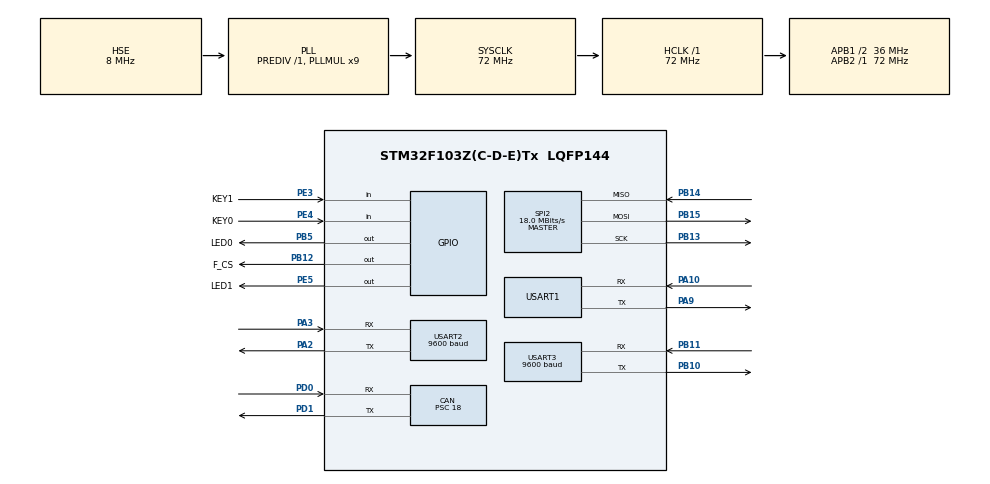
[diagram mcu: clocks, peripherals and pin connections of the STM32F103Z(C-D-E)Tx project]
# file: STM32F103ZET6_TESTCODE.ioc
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CAN.BS2=CAN_BS2_2TQ
CAN.CalculateBaudRate=500000
CAN.CalculateTimeBit=2000
CAN.CalculateTimeQuantum=500.0
CAN.Prescaler=18
FREERTOS.Queues01=ShortQueue,16,uint16_t,0,Dynamic,NULL,NULL;LongQueue,128,uint16_t,0,Dynamic,NULL,NULL
FREERTOS.Tasks01=Start_Task,24,128,Start_Thread,Default,NULL,Dynamic,NULL,NULL;Mb_Master,8,512,Mb_Master_Thread,Default,NULL,Dynamic,NULL,NULL;Mb_Slaver,8,512,Mb_Slaver_Thread,Default,NULL,Dynamic,NULL,NULL;PE_Comm,8,512,PE_Comm_Thread,Default,NULL,Dynamic,NULL,NULL;Ymbdem,8,2048,Ymbdem_Thread,Default,NULL,Dynamic,NULL,NULL;Task_Mem,8,1024,Task_Mem_Thread,Default,NULL,Dynamic,NULL,NULL
FREERTOS.configCHECK_FOR_STACK_OVERFLOW=2
FREERTOS.configTOTAL_HEAP_SIZE=0x8000
Mcu.Family=STM32F1
Mcu.Name=STM32F103Z(C-D-E)Tx
Mcu.Package=LQFP144
NVIC.PriorityGroup=NVIC_PRIORITYGROUP_4
NVIC.SPI2_IRQn=true\:6\:0\:true\:false\:true\:true\:true\:true\:true
NVIC.TIM6_IRQn=true\:7\:0\:true\:false\:true\:true\:true\:true\:true
NVIC.USART1_IRQn=true\:7\:0\:true\:false\:true\:true\:true\:true\:true
NVIC.USART2_IRQn=true\:7\:0\:true\:false\:true\:true\:true\:true\:true
NVIC.USART3_IRQn=true\:7\:0\:true\:false\:true\:true\:true\:true\:true
NVIC.USB_LP_CAN1_RX0_IRQn=true\:8\:0\:true\:false\:true\:true\:true\:true\:true
OSC_IN.Mode=HSE-External-Oscillator
OSC_IN.Signal=RCC_OSC_IN
OSC_OUT.Mode=HSE-External-Oscillator
OSC_OUT.Signal=RCC_OSC_OUT
PA10.Mode=Asynchronous
PA10.Signal=USART1_RX
PA13.Mode=JTAG_5_pins
PA13.Signal=SYS_JTMS-SWDIO
PA14.Mode=JTAG_5_pins
PA14.Signal=SYS_JTCK-SWCLK
PA15.Mode=JTAG_5_pins
PA15.Signal=SYS_JTDI
PA2.Mode=Asynchronous
PA2.Signal=USART2_TX
PA3.Mode=Asynchronous
PA3.Signal=USART2_RX
PA9.Mode=Asynchronous
PA9.Signal=USART1_TX
PB10.Mode=Asynchronous
PB10.Signal=USART3_TX
PB11.Mode=Asynchronous
PB11.Signal=USART3_RX
PB12.GPIO_Label=F_CS
PB12.GPIO_PuPd=GPIO_PULLUP
PB12.GPIO_Speed=GPIO_SPEED_FREQ_HIGH
PB12.Signal=GPIO_Output
PB13.Mode=Full_Duplex_Master
PB13.Signal=SPI2_SCK
PB14.Mode=Full_Duplex_Master
PB14.Signal=SPI2_MISO
PB15.Mode=Full_Duplex_Master
PB15.Signal=SPI2_MOSI
PB3.Mode=JTAG_5_pins
PB3.Signal=SYS_JTDO-TRACESWO
PB4.Mode=JTAG_5_pins
PB4.Signal=SYS_NJTRST
PB5.GPIO_Label=LED0
PB5.GPIO_PuPd=GPIO_PULLUP
PB5.GPIO_Speed=GPIO_SPEED_FREQ_HIGH
PB5.Signal=GPIO_Output
PC14-OSC32_IN.Mode=LSE-External-Oscillator
PC14-OSC32_IN.Signal=RCC_OSC32_IN
PC15-OSC32_OUT.Mode=LSE-External-Oscillator
PC15-OSC32_OUT.Signal=RCC_OSC32_OUT
PD0.Mode=CAN_Activate
PD0.Signal=CAN_RX
PD1.Mode=CAN_Activate
PD1.Signal=CAN_TX
PE3.GPIO_Label=KEY1
PE3.Signal=GPIO_Input
PE4.GPIO_Label=KEY0
PE4.Signal=GPIO_Input
PE5.GPIO_Label=LED1
PE5.GPIO_PuPd=GPIO_PULLUP
PE5.GPIO_Speed=GPIO_SPEED_FREQ_HIGH
PE5.Signal=GPIO_Output
ProjectManager.HeapSize=0x200
ProjectManager.StackSize=0x400
ProjectManager.TargetToolchain=MDK-ARM V5.32
RCC.AHBFreq_Value=72000000
RCC.APB1CLKDivider=RCC_HCLK_DIV2
RCC.APB1Freq_Value=36000000
RCC.APB1TimFreq_Value=72000000
RCC.APB2Freq_Value=72000000
RCC.APB2TimFreq_Value=72000000
RCC.HCLKFreq_Value=72000000
RCC.PLLMUL=RCC_PLL_MUL9
RCC.PLLSourceVirtual=RCC_PLLSOURCE_HSE
RCC.SYSCLKFreq_VALUE=72000000
RCC.SYSCLKSource=RCC_SYSCLKSOURCE_PLLCLK
RCC.USBFreq_Value=72000000
SPI2.BaudRatePrescaler=SPI_BAUDRATEPRESCALER_2
SPI2.CLKPhase=SPI_PHASE_1EDGE
SPI2.CLKPolarity=SPI_POLARITY_LOW
SPI2.CalculateBaudRate=18.0 MBits/s
SPI2.Direction=SPI_DIRECTION_2LINES
SPI2.Mode=SPI_MODE_MASTER
SPI2.VirtualType=VM_MASTER
TIM6.AutoReloadPreload=TIM_AUTORELOAD_PRELOAD_ENABLE
TIM6.Period=4999
TIM6.Prescaler=143
USART1.VirtualMode=VM_ASYNC
USART2.BaudRate=9600
USART2.VirtualMode=VM_ASYNC
USART3.BaudRate=9600
USART3.VirtualMode=VM_ASYNC
VP_FREERTOS_VS_CMSIS_V2.Mode=CMSIS_V2
VP_IWDG_VS_IWDG.Mode=IWDG_Activate
VP_RTC_VS_RTC_Activate.Mode=RTC_Enabled
VP_RTC_VS_RTC_Calendar.Mode=RTC_Calendar
VP_TIM6_VS_ClockSourceINT.Mode=Enable_Timer
board=custom

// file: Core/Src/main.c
/* USER CODE BEGIN Header */
/**
  ******************************************************************************
  * @file           : main.c
  * @brief          : Main program body
  ******************************************************************************
  * @attention
  *
  * Copyright (c) 2022 STMicroelectronics.
  * All rights reserved.
  *
  * This software is licensed under terms that can be found in the LICENSE file
  * in the root directory of this software component.
  * If no LICENSE file comes with this software, it is provided AS-IS.
  *
  ******************************************************************************
  */
/* USER CODE END Header */
#include "main.h"
#include "cmsis_os.h"
#include "can.h"
#include "iwdg.h"
#include "rtc.h"
#include "spi.h"
#include "tim.h"
#include "usart.h"
#include "gpio.h"

void SystemClock_Config(void);
void MX_FREERTOS_Init(void);

int main(void)
{

  /* MCU Configuration--------------------------------------------------------*/

  /* Reset of all peripherals, Initializes the Flash interface and the Systick. */
  HAL_Init();

  /* Configure the system clock */
  SystemClock_Config();

  /* Initialize all configured peripherals */
  MX_GPIO_Init();
  MX_CAN_Init();
//  MX_IWDG_Init();
  MX_RTC_Init();
  MX_SPI2_Init();
  MX_USART1_UART_Init();
  MX_USART2_UART_Init();
  MX_TIM6_Init();
  MX_USART3_UART_Init();

  /* Init scheduler */
  osKernelInitialize();  /* Call init function for freertos objects (in freertos.c) */
  MX_FREERTOS_Init();

  /* Start scheduler */
  osKernelStart();

  /* We should never get here as control is now taken by the scheduler */
  /* Infinite loop */
  while (1)
  {

  }
}

void SystemClock_Config(void)
{
  RCC_OscInitTypeDef RCC_OscInitStruct = {0};
  RCC_ClkInitTypeDef RCC_ClkInitStruct = {0};
  RCC_PeriphCLKInitTypeDef PeriphClkInit = {0};

  /** Initializes the RCC Oscillators according to the specified parameters
  * in the RCC_OscInitTypeDef structure.
  */
  RCC_OscInitStruct.OscillatorType = RCC_OSCILLATORTYPE_LSI|RCC_OSCILLATORTYPE_HSE;
  RCC_OscInitStruct.HSEState = RCC_HSE_ON;
  RCC_OscInitStruct.HSEPredivValue = RCC_HSE_PREDIV_DIV1;
  RCC_OscInitStruct.HSIState = RCC_HSI_ON;
  RCC_OscInitStruct.LSIState = RCC_LSI_ON;
  RCC_OscInitStruct.PLL.PLLState = RCC_PLL_ON;
  RCC_OscInitStruct.PLL.PLLSource = RCC_PLLSOURCE_HSE;
  RCC_OscInitStruct.PLL.PLLMUL = RCC_PLL_MUL9;
  if (HAL_RCC_OscConfig(&RCC_OscInitStruct) != HAL_OK)
  {
    Error_Handler();
  }

  /** Initializes the CPU, AHB and APB buses clocks
  */
  RCC_ClkInitStruct.ClockType = RCC_CLOCKTYPE_HCLK|RCC_CLOCKTYPE_SYSCLK
                              |RCC_CLOCKTYPE_PCLK1|RCC_CLOCKTYPE_PCLK2;
  RCC_ClkInitStruct.SYSCLKSource = RCC_SYSCLKSOURCE_PLLCLK;
  RCC_ClkInitStruct.AHBCLKDivider = RCC_SYSCLK_DIV1;
  RCC_ClkInitStruct.APB1CLKDivider = RCC_HCLK_DIV2;
  RCC_ClkInitStruct.APB2CLKDivider = RCC_HCLK_DIV1;

  if (HAL_RCC_ClockConfig(&RCC_ClkInitStruct, FLASH_LATENCY_2) != HAL_OK)
  {
    Error_Handler();
  }
  PeriphClkInit.PeriphClockSelection = RCC_PERIPHCLK_RTC;
  PeriphClkInit.RTCClockSelection = RCC_RTCCLKSOURCE_LSI;
  if (HAL_RCCEx_PeriphCLKConfig(&PeriphClkInit) != HAL_OK)
  {
    Error_Handler();
  }
}

void Error_Handler(void)
{
  __disable_irq();
  while (1)
  {
  }
}

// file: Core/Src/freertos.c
/* USER CODE BEGIN Header */
/**
  ******************************************************************************
  * File Name          : freertos.c
  * Description        : Code for freertos applications
  ******************************************************************************
  * @attention
  *
  * Copyright (c) 2022 STMicroelectronics.
  * All rights reserved.
  *
  * This software is licensed under terms that can be found in the LICENSE file
  * in the root directory of this software component.
  * If no LICENSE file comes with this software, it is provided AS-IS.
  *
  ******************************************************************************
  */
/* USER CODE END Header */

#include "FreeRTOS.h"
#include "task.h"
#include "main.h"
#include "cmsis_os.h"
#include "tim.h"
/* USER CODE BEGIN Includes */
#include "user_mb_app.h"
/* USER CODE END Includes */

/* Definitions for Start_Task */
osThreadId_t Start_TaskHandle;
const osThreadAttr_t Start_Task_attributes = {
  .name = "Start_Task",
  .stack_size = 128 * 4,
  .priority = (osPriority_t) osPriorityNormal,
};
/////* Definitions for Mb_Master */
////osThreadId_t Mb_MasterHandle;
////const osThreadAttr_t Mb_Master_attributes = {
////  .name = "Mb_Master",
////  .stack_size = 512 * 4,
////  .priority = (osPriority_t) osPriorityLow,
////};
/////* Definitions for Mb_Slaver */
////osThreadId_t Mb_SlaverHandle;
////const osThreadAttr_t Mb_Slaver_attributes = {
////  .name = "Mb_Slaver",
////  .stack_size = 512 * 4,
////  .priority = (osPriority_t) osPriorityLow,
////};
/////* Definitions for PE_Comm */
////osThreadId_t PE_CommHandle;
////const osThreadAttr_t PE_Comm_attributes = {
////  .name = "PE_Comm",
////  .stack_size = 512 * 4,
////  .priority = (osPriority_t) osPriorityLow,
////};
/////* Definitions for Ymbdem */
////osThreadId_t YmbdemHandle;
////const osThreadAttr_t Ymbdem_attributes = {
////  .name = "Ymbdem",
////  .stack_size = 2048 * 4,
////  .priority = (osPriority_t) osPriorityLow,
////};
/////* Definitions for Task_Mem */
////osThreadId_t Task_MemHandle;
////const osThreadAttr_t Task_Mem_attributes = {
////  .name = "Task_Mem",
////  .stack_size = 1024 * 4,
////  .priority = (osPriority_t) osPriorityLow,
////};
/////* Definitions for ShortQueue */
////osMessageQueueId_t ShortQueueHandle;
////const osMessageQueueAttr_t ShortQueue_attributes = {
////  .name = "ShortQueue"
////};
/////* Definitions for LongQueue */
////osMessageQueueId_t LongQueueHandle;
////const osMessageQueueAttr_t LongQueue_attributes = {
////  .name = "LongQueue"
////};

void Start_Thread(void *argument);
void Mb_Master_Thread(void *argument);
void Mb_Slaver_Thread(void *argument);
void PE_Comm_Thread(void *argument);
void Ymbdem_Thread(void *argument);
void Task_Mem_Thread(void *argument);

void MX_FREERTOS_Init(void); /* (MISRA C 2004 rule 8.1) */

/* Hook prototypes */
void vApplicationStackOverflowHook(xTaskHandle xTask, signed char *pcTaskName);

/* USER CODE BEGIN 4 */
void vApplicationStackOverflowHook(xTaskHandle xTask, signed char *pcTaskName)
{
   /* Run time stack overflow checking is performed if
   configCHECK_FOR_STACK_OVERFLOW is defined to 1 or 2. This hook function is
   called if a stack overflow is detected. */
}
/* USER CODE END 4 */

////void MX_FREERTOS_Init1(void) {
////  /* USER CODE BEGIN Init */

////  /* USER CODE END Init */

////  /* USER CODE BEGIN RTOS_MUTEX */
////  /* add mutexes, ... */
////  /* USER CODE END RTOS_MUTEX */

////  /* USER CODE BEGIN RTOS_SEMAPHORES */
////  /* add semaphores, ... */
////  /* USER CODE END RTOS_SEMAPHORES */

////  /* USER CODE BEGIN RTOS_TIMERS */
////  /* start timers, add new ones, ... */
////  /* USER CODE END RTOS_TIMERS */

////  /* Create the queue(s) */
////  /* creation of ShortQueue */
////  ShortQueueHandle = osMessageQueueNew (16, sizeof(uint16_t), &ShortQueue_attributes);

////  /* creation of LongQueue */
////  LongQueueHandle = osMessageQueueNew (128, sizeof(uint16_t), &LongQueue_attributes);

////  /* USER CODE BEGIN RTOS_QUEUES */
////  /* add queues, ... */
////  /* USER CODE END RTOS_QUEUES */

////  /* Create the thread(s) */
////  /* creation of Start_Task */
////  Start_TaskHandle = osThreadNew(Start_Thread, NULL, &Start_Task_attributes);

////  /* creation of Mb_Master */
////  Mb_MasterHandle = osThreadNew(Mb_Master_Thread, NULL, &Mb_Master_attributes);

////  /* creation of Mb_Slaver */
////  Mb_SlaverHandle = osThreadNew(Mb_Slaver_Thread, NULL, &Mb_Slaver_attributes);

////  /* creation of PE_Comm */
////  PE_CommHandle = osThreadNew(PE_Comm_Thread, NULL, &PE_Comm_attributes);

////  /* creation of Ymbdem */
////  YmbdemHandle = osThreadNew(Ymbdem_Thread, NULL, &Ymbdem_attributes);

////  /* creation of Task_Mem */
////  Task_MemHandle = osThreadNew(Task_Mem_Thread, NULL, &Task_Mem_attributes);

////  /* USER CODE BEGIN RTOS_THREADS */
////  /* add threads, ... */
////  /* USER CODE END RTOS_THREADS */

////  /* USER CODE BEGIN RTOS_EVENTS */
////  /* add events, ... */
////  /* USER CODE END RTOS_EVENTS */

////}

/*主机任务*/
osThreadId_t MasterTaskHandle;
const osThreadAttr_t MasterTask_attributes = {
    .name = "MasterTask",
    .priority = (osPriority_t) osPriorityLow,
    .stack_size = 128 * 4};

/*从机任务*/
osThreadId_t SlaveTaskHandle;
const osThreadAttr_t SlaveTask_attributes = {
    .name = "SlaveTask",
    .priority = (osPriority_t) osPriorityLow,
    .stack_size = 128 * 4};

/*写任务*/
osThreadId_t WriteTaskHandle;
const osThreadAttr_t Write_TASK = {
    .name = "Write_Task",
    .priority = (osPriority_t) osPriorityLow,
    .stack_size = 128 * 8};

/*读任务*/
osThreadId_t ReadTaskHandle;
const osThreadAttr_t Read_Task = {
    .name = "Read_Task",
    .priority = (osPriority_t) osPriorityLow,
    .stack_size = 128 * 8};

void MasterTask(void *argument);
void SlaveTask(void *argument);
void StartWriteTask(void *argument);
void StartReadTask(void *argument);

void MX_FREERTOS_Init(void)
{
  HAL_TIM_Base_Start(&htim6); //开启帧率测试
  eMBMasterInit(MB_RTU, 2, 115200, MB_PAR_NONE); /*主机初始化*/
  eMBMasterEnable();	/*主机使能*/
//  vMBMasterRunResRelease();
  /* creation of Start_Task */
  Start_TaskHandle = osThreadNew(Start_Thread, NULL, &Start_Task_attributes);

//  eMBInit(MB_RTU, 0x01, 3, 38400, MB_PAR_NONE); /*从机初始化*/
//  eMBEnable();	/*从机使能*/
	/*创建写任务*/
  WriteTaskHandle = osThreadNew(StartWriteTask, NULL, &Write_TASK);
	/*创建主机任务*/
  MasterTaskHandle = osThreadNew(MasterTask, NULL, &MasterTask_attributes);
	/*创建读任务*/
	ReadTaskHandle = osThreadNew(StartReadTask, NULL, &Read_Task);
	/*创建从机任务*/
// SlaveTaskHandle = osThreadNew(SlaveTask, NULL, &SlaveTask_attributes);

}

void StartWriteTask(void *argument)
{
//	vTaskSuspend(ReadTaskHandle);
	eMBMasterReqErrCode ret;
//  uint16_t data[] = {0,1,1,1};
	uint16_t data[10] = {6,2,3,4,5,8,2,50,10,11};
	unsigned long H_value;
//	ret = eMBMasterReqWriteHoldingRegister(1, 1, data[0], 100);
//	vMBMasterRunResRelease();
  for (;;)
  {
		H_value = uxTaskGetStackHighWaterMark(WriteTaskHandle);
		//printf("H_value:%d\r\n", (int)H_value);
		/*写单个寄存器*/
//		ret = eMBMasterReqWriteHoldingRegister(1, 5400, 8, 100);

		/*写多个寄存器*/
		ret = eMBMasterReqWriteMultipleHoldingRegister(1, 5400, 10, data, 100);
		//printf("ret values :%d ", ret);
   		 for(uint8_t i=0;i<sizeof(data)/sizeof(uint16_t);i++)
		{
     		 data[i]++;
		}
		osDelay(1000);
//		vTaskResume(ReadTaskHandle);
//		vTaskSuspend(WriteTaskHandle);
//		vTaskDelete(NULL);
  }
}

void StartReadTask(void *argument)
{
//	vTaskSuspend(WriteTaskHandle);
	extern USHORT usMRegHoldBuf[MB_MASTER_TOTAL_SLAVE_NUM][M_REG_HOLDING_NREGS];
	eMBMasterReqErrCode ret;
	uint16_t slaveid;
	uint16_t regaddr;
	uint16_t regnums;
	uint8_t i;

	for (;;)
 	{
		slaveid = 1;
		regaddr = 5400;
		regnums = 10;
		/*读多个寄存器*/
		ret = eMBMasterReqReadHoldingRegister(slaveid, regaddr, regnums, 1000);
		if(ret == MB_MRE_NO_ERR)
		{
			//printf("===eMBMasterReqReadHoldingRegister successful! values : ");
			for(i = 0; i < regnums; i++)
			{
				//printf("%d ", usMRegHoldBuf[slaveid-1][i]);
			}
			//printf("\r\n");
		}
		else
		{
			//printf("===eMBMasterReqReadHoldingRegister failed! ret = %d \r\n", ret);
			for(i = 0; i < regnums; i++)
			{
				//printf("%d ", usMRegHoldBuf[slaveid-1][i]);
			}
		}
		osDelay(1000);
//		vTaskResume(WriteTaskHandle);
//		vTaskSuspend(ReadTaskHandle);
//		vTaskDelete(ReadTaskHandle);
	}
}

void MasterTask(void *argument)
{
  for (;;)
  {
    eMBMasterPoll();		/*主机轮询*/
	osDelay(50);
  }
}

void SlaveTask(void *argument)
{
  for (;;)
  {
//    eMBPoll();		/*从机轮询*/
    osDelay(500);
  }
}

void Start_Thread(void *argument)
{
  /* USER CODE BEGIN Start_Thread */
  /* Infinite loop */
  for(;;)
  {
		HAL_GPIO_TogglePin(LED0_GPIO_Port, LED0_Pin);
		osDelay(1000);
  }
  /* USER CODE END Start_Thread */
}

void Mb_Master_Thread(void *argument)
{
  /* USER CODE BEGIN Mb_Master_Thread */
  /* Infinite loop */
  for(;;)
  {
		osDelay(500);
  }
  /* USER CODE END Mb_Master_Thread */
}

void Mb_Slaver_Thread(void *argument)
{
	for(;;)
	{
		osDelay(1);
	}
}

void PE_Comm_Thread(void *argument)
{
  for(;;)
  {
    osDelay(1);
  }
}

void Ymbdem_Thread(void *argument)
{
  for(;;)
  {
    osDelay(1);
  }
}

void Task_Mem_Thread(void *argument)
{
  for(;;)
  {
    osDelay(1);
  }
}
